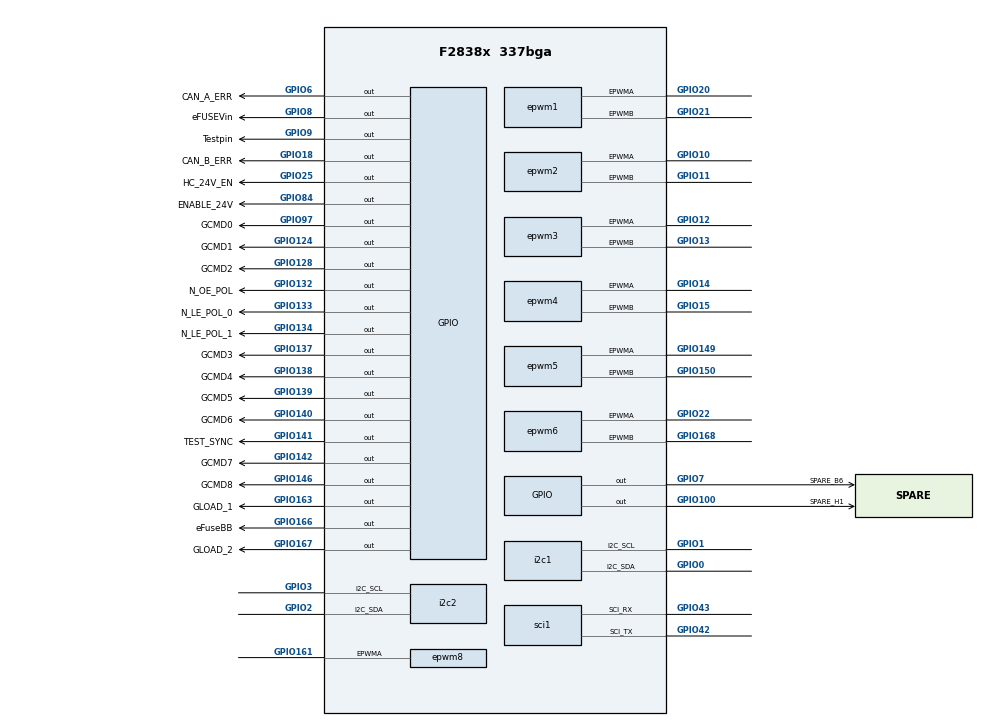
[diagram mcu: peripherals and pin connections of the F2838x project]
/**
 * @cliArgs --device "F2838x" --package "337bga" --part "F2838x_337bga" --context "CPU1" --product "C2000WARE@4.02.00.00"
 * @versions {"tool":"1.17.0+3128"}
 */

/**
 * Import the modules used in this configuration.
 */
const cputimer         = scripting.addModule("/driverlib/cputimer.js", {}, false);
const cputimer1        = cputimer.addInstance();
const dma              = scripting.addModule("/driverlib/dma.js", {}, false);
const dma1             = dma.addInstance();
const epwm             = scripting.addModule("/driverlib/epwm.js", {}, false);
const epwm1            = epwm.addInstance();
const epwm2            = epwm.addInstance();
const epwm3            = epwm.addInstance();
const epwm4            = epwm.addInstance();
const epwm5            = epwm.addInstance();
const epwm6            = epwm.addInstance();
const epwm7            = epwm.addInstance();
const epwm8            = epwm.addInstance();
const gpio             = scripting.addModule("/driverlib/gpio.js", {}, false);
const gpio1            = gpio.addInstance();
const gpio2            = gpio.addInstance();
const gpio3            = gpio.addInstance();
const gpio4            = gpio.addInstance();
const gpio5            = gpio.addInstance();
const gpio6            = gpio.addInstance();
const gpio7            = gpio.addInstance();
const gpio8            = gpio.addInstance();
const gpio9            = gpio.addInstance();
const gpio10           = gpio.addInstance();
const gpio11           = gpio.addInstance();
const gpio12           = gpio.addInstance();
const gpio13           = gpio.addInstance();
const gpio14           = gpio.addInstance();
const gpio15           = gpio.addInstance();
const gpio16           = gpio.addInstance();
const gpio17           = gpio.addInstance();
const gpio18           = gpio.addInstance();
const gpio19           = gpio.addInstance();
const gpio20           = gpio.addInstance();
const gpio21           = gpio.addInstance();
const gpio22           = gpio.addInstance();
const gpio23           = gpio.addInstance();
const gpio24           = gpio.addInstance();
const i2c              = scripting.addModule("/driverlib/i2c.js", {}, false);
const i2c1             = i2c.addInstance();
const i2c2             = i2c.addInstance();
const inputxbar_input  = scripting.addModule("/driverlib/inputxbar_input.js", {}, false);
const inputxbar_input1 = inputxbar_input.addInstance();
const inputxbar_input2 = inputxbar_input.addInstance();
const inputxbar_input3 = inputxbar_input.addInstance();
const memcfg           = scripting.addModule("/driverlib/memcfg.js");
const sci              = scripting.addModule("/driverlib/sci.js", {}, false);
const sci1             = sci.addInstance();
const sysctl           = scripting.addModule("/driverlib/sysctl.js");

/**
 * Write custom configuration values to the imported modules.
 */
cputimer1.cputimerBase             = "CPUTIMER2_BASE";
cputimer1.timerPrescaler           = 1000;
cputimer1.timerPeriod              = 200;
cputimer1.registerInterrupts       = true;
cputimer1.startTimer               = true;
cputimer1.enableInterrupt          = true;
cputimer1.$name                    = "myCPUTIMER2";
cputimer1.timerInt.enableInterrupt = true;

dma1.dmaBase                = "DMA_CH2_BASE";
dma1.useInterrupts          = true;
dma1.interruptMode          = "DMA_INT_AT_END";
dma1.$name                  = "CPU1_EXT_MEM";
dma1.enableTriggers         = true;
dma1.srcBurstStep           = 1;
dma1.destBurstStep          = 1;
dma1.srcAddressVariable     = "srcAddr";
dma1.destAddressVariable    = "destAddr";
dma1.registerInterrupts     = true;
dma1.enableInterrupts       = true;
dma1.destTransferStep       = 1;
dma1.srcTransferStep        = 1;
dma1.burstSize              = 16;
dma1.dmaInt.enableInterrupt = true;

epwm1.$name                                                               = "BEG_1_2";
epwm1.epwmTimebase_period                                                 = 714;
epwm1.epwmActionQualifier_EPWM_AQ_OUTPUT_A_ON_TIMEBASE_ZERO               = "EPWM_AQ_OUTPUT_HIGH";
epwm1.epwmActionQualifier_EPWM_AQ_OUTPUT_A_ON_TIMEBASE_UP_CMPA            = "EPWM_AQ_OUTPUT_LOW";
epwm1.epwmDeadband_polarityFED                                            = "EPWM_DB_POLARITY_ACTIVE_LOW";
epwm1.epwmDeadband_delayRED                                               = 10;
epwm1.epwmDeadband_delayFED                                               = 10;
epwm1.epwmTimebase_hsClockDiv                                             = "EPWM_HSCLOCK_DIVIDER_1";
epwm1.epwmEventTrigger_EPWM_SOC_A_triggerEnable                           = true;
epwm1.epwmEventTrigger_EPWM_SOC_A_triggerSource                           = "EPWM_SOC_TBCTR_ZERO";
epwm1.epwmEventTrigger_EPWM_SOC_B_triggerEnable                           = true;
epwm1.epwmEventTrigger_EPWM_SOC_B_triggerSource                           = "EPWM_SOC_TBCTR_U_CMPA";
epwm1.epwmDeadband_enableRED                                              = true;
epwm1.epwmDeadband_enableFED                                              = true;
epwm1.epwmActionQualifier_EPWM_AQ_OUTPUT_A_shadowMode                     = true;
epwm1.epwmActionQualifier_EPWM_AQ_OUTPUT_A_shadowEvent                    = "EPWM_AQ_LOAD_ON_CNTR_PERIOD";
epwm1.epwmCounterCompare_cmpA                                             = 714;
epwm1.epwmTripZone_oneShotSource                                          = ["EPWM_TZ_SIGNAL_OSHT3"];
epwm1.epwmTripZone_cbcPulse                                               = "EPWM_TZ_CBC_PULSE_CLR_CNTR_PERIOD";
epwm1.epwmTripZone_tzInterruptSource                                      = ["EPWM_TZ_INTERRUPT_OST"];
epwm1.epwmDigitalCompare_EPWM_TZ_DC_OUTPUT_A2                             = "EPWM_TZ_EVENT_DCXH_LOW";
epwm1.epwmDigitalCompare_EPWM_DC_MODULE_A_EPWM_DC_EVENT_1_latchMode       = "EPWM_DC_CBC_LATCH_ENABLED";
epwm1.epwmDigitalCompare_EPWM_DC_MODULE_A_EPWM_DC_EVENT_1_latchClearEvent = "EPWM_DC_CBC_LATCH_CLR_ON_CNTR_PERIOD";
epwm1.epwmDigitalCompare_EPWM_DC_MODULE_A_EPWM_DC_EVENT_2_latchMode       = "EPWM_DC_CBC_LATCH_ENABLED";
epwm1.epwmDigitalCompare_EPWM_DC_MODULE_A_EPWM_DC_EVENT_2_latchClearEvent = "EPWM_DC_CBC_LATCH_CLR_ON_CNTR_PERIOD";
epwm1.epwmDigitalCompare_EPWM_DC_MODULE_B_EPWM_DC_EVENT_1_latchMode       = "EPWM_DC_CBC_LATCH_ENABLED";
epwm1.epwmDigitalCompare_EPWM_DC_MODULE_B_EPWM_DC_EVENT_2_latchMode       = "EPWM_DC_CBC_LATCH_ENABLED";
epwm1.epwmEventTrigger_EPWM_SOC_A_triggerEventPrescalar                   = "2";
epwm1.epwmEventTrigger_EPWM_SOC_A_triggerEventCountInitEnable             = true;
epwm1.epwmEventTrigger_EPWM_SOC_B_triggerEventPrescalar                   = "2";
epwm1.epwmEventTrigger_EPWM_SOC_B_triggerEventCountInitEnable             = true;
epwm1.epwmTimebase_syncInPulseSource                                      = "EPWM_SYNC_IN_PULSE_SRC_DISABLE";
epwm1.epwmTimebase_emulationMode                                          = "EPWM_EMULATION_FREE_RUN";
epwm1.hrpwm_syncSource                                                    = "HRPWM_PWMSYNC_SOURCE_COMPC_UP";
epwm1.epwmTimebase_syncOutPulseMode                                       = ["EPWM_SYNC_OUT_PULSE_ON_CNTR_COMPARE_C"];
epwm1.epwm.$assign                                                        = "EPWM11";
epwm1.epwm.epwmaPin.$assign                                               = "GPIO20";
epwm1.epwm.epwmbPin.$assign                                               = "GPIO21";

epwm2.$name                                                    = "QABPWM_12_13";
epwm2.epwmTimebase_emulationMode                               = "EPWM_EMULATION_FREE_RUN";
epwm2.epwmTimebase_hsClockDiv                                  = "EPWM_HSCLOCK_DIVIDER_1";
epwm2.epwmTimebase_period                                      = 386;
epwm2.epwmTimebase_phaseEnable                                 = true;
epwm2.epwmTimebase_forceSyncPulse                              = true;
epwm2.epwmTimebase_syncInPulseSource                           = "EPWM_SYNC_IN_PULSE_SRC_DISABLE";
epwm2.epwmTimebase_syncOutPulseMode                            = ["EPWM_SYNC_OUT_PULSE_ON_CNTR_COMPARE_C"];
epwm2.hrpwm_syncSource                                         = "HRPWM_PWMSYNC_SOURCE_COMPC_UP";
epwm2.epwmCounterCompare_cmpA                                  = 193;
epwm2.epwmActionQualifier_EPWM_AQ_OUTPUT_A_ON_TIMEBASE_ZERO    = "EPWM_AQ_OUTPUT_HIGH";
epwm2.epwmActionQualifier_EPWM_AQ_OUTPUT_A_ON_TIMEBASE_UP_CMPA = "EPWM_AQ_OUTPUT_LOW";
epwm2.epwmTripZone_EPWM_TZ_ACTION_EVENT_TZA                    = "EPWM_TZ_ACTION_LOW";
epwm2.epwmTripZone_EPWM_TZ_ACTION_EVENT_TZB                    = "EPWM_TZ_ACTION_LOW";
epwm2.epwmTripZone_cbcSource                                   = ["EPWM_TZ_SIGNAL_DCAEVT2"];
epwm2.epwmDeadband_polarityFED                                 = "EPWM_DB_POLARITY_ACTIVE_LOW";
epwm2.epwmDeadband_enableRED                                   = true;
epwm2.epwmDeadband_delayRED                                    = 4;
epwm2.epwmDeadband_enableFED                                   = true;
epwm2.epwmDeadband_delayFED                                    = 4;
epwm2.epwm.$assign                                             = "EPWM6";
epwm2.epwm.epwmaPin.$assign                                    = "GPIO10";
epwm2.epwm.epwmbPin.$assign                                    = "GPIO11";

epwm3.$name                                                    = "QABPWM_14_15";
epwm3.epwmTimebase_emulationMode                               = "EPWM_EMULATION_FREE_RUN";
epwm3.epwmTimebase_hsClockDiv                                  = "EPWM_HSCLOCK_DIVIDER_1";
epwm3.epwmTimebase_period                                      = 386;
epwm3.epwmTimebase_periodLink                                  = "EPWM_LINK_WITH_EPWM_6";
epwm3.epwmTimebase_phaseEnable                                 = true;
epwm3.epwmTimebase_phaseShift                                  = 2;
epwm3.epwmTimebase_syncInPulseSource                           = "EPWM_SYNC_IN_PULSE_SRC_SYNCOUT_EPWM6";
epwm3.hrpwm_syncSource                                         = "HRPWM_PWMSYNC_SOURCE_COMPC_UP";
epwm3.epwmCounterCompare_cmpA                                  = 193;
epwm3.epwmCounterCompare_cmpALink                              = "EPWM_LINK_WITH_EPWM_6";
epwm3.epwmActionQualifier_EPWM_AQ_OUTPUT_A_ON_TIMEBASE_ZERO    = "EPWM_AQ_OUTPUT_HIGH";
epwm3.epwmActionQualifier_EPWM_AQ_OUTPUT_A_ON_TIMEBASE_UP_CMPA = "EPWM_AQ_OUTPUT_LOW";
epwm3.epwmDeadband_polarityFED                                 = "EPWM_DB_POLARITY_ACTIVE_LOW";
epwm3.epwmDeadband_enableRED                                   = true;
epwm3.epwmDeadband_delayRED                                    = 4;
epwm3.epwmDeadband_enableFED                                   = true;
epwm3.epwmDeadband_delayFED                                    = 4;
epwm3.epwmDeadband_outputSwapOutA                              = true;
epwm3.epwmDeadband_outputSwapOutB                              = true;
epwm3.epwm.$assign                                             = "EPWM7";
epwm3.epwm.epwmaPin.$assign                                    = "GPIO12";
epwm3.epwm.epwmbPin.$assign                                    = "GPIO13";

epwm4.$name                                                    = "QABPWM_4_5";
epwm4.epwmTimebase_hsClockDiv                                  = "EPWM_HSCLOCK_DIVIDER_1";
epwm4.epwmTimebase_period                                      = 386;
epwm4.epwmTimebase_syncInPulseSource                           = "EPWM_SYNC_IN_PULSE_SRC_DISABLE";
epwm4.epwmTimebase_syncOutPulseMode                            = ["EPWM_SYNC_OUT_PULSE_ON_CNTR_ZERO"];
epwm4.epwmCounterCompare_cmpA                                  = 193;
epwm4.epwmActionQualifier_EPWM_AQ_OUTPUT_A_ON_TIMEBASE_ZERO    = "EPWM_AQ_OUTPUT_HIGH";
epwm4.epwmActionQualifier_EPWM_AQ_OUTPUT_A_ON_TIMEBASE_UP_CMPA = "EPWM_AQ_OUTPUT_LOW";
epwm4.epwmTripZone_EPWM_TZ_ACTION_EVENT_TZA                    = "EPWM_TZ_ACTION_LOW";
epwm4.epwmTripZone_EPWM_TZ_ACTION_EVENT_TZB                    = "EPWM_TZ_ACTION_LOW";
epwm4.epwmTripZone_cbcSource                                   = ["EPWM_TZ_SIGNAL_DCAEVT2"];
epwm4.epwmDeadband_polarityFED                                 = "EPWM_DB_POLARITY_ACTIVE_LOW";
epwm4.epwmDeadband_enableRED                                   = true;
epwm4.epwmDeadband_delayRED                                    = 4;
epwm4.epwmDeadband_enableFED                                   = true;
epwm4.epwmDeadband_delayFED                                    = 4;
epwm4.epwm.$assign                                             = "EPWM8";
epwm4.epwm.epwmaPin.$assign                                    = "GPIO14";
epwm4.epwm.epwmbPin.$assign                                    = "GPIO15";

epwm5.$name                          = "QABPWM_6_7";
epwm5.epwmTimebase_hsClockDiv        = "EPWM_HSCLOCK_DIVIDER_1";
epwm5.epwmTimebase_period            = 386;
epwm5.epwmTimebase_periodLink        = "EPWM_LINK_WITH_EPWM_8";
epwm5.epwmTimebase_phaseEnable       = true;
epwm5.epwmTimebase_phaseShift        = 2;
epwm5.epwmTimebase_forceSyncPulse    = true;
epwm5.epwmTimebase_syncInPulseSource = "EPWM_SYNC_IN_PULSE_SRC_SYNCOUT_EPWM8";
epwm5.epwmTimebase_syncOutPulseMode  = ["EPWM_SYNC_OUT_PULSE_ON_CNTR_ZERO"];
epwm5.epwmCounterCompare_cmpA        = 193;
epwm5.epwmCounterCompare_cmpALink    = "EPWM_LINK_WITH_EPWM_8";
epwm5.epwmDeadband_polarityFED       = "EPWM_DB_POLARITY_ACTIVE_LOW";
epwm5.epwmDeadband_enableRED         = true;
epwm5.epwmDeadband_delayRED          = 4;
epwm5.epwmDeadband_enableFED         = true;
epwm5.epwmDeadband_delayFED          = 4;
epwm5.epwmDeadband_outputSwapOutB    = true;
epwm5.epwmDeadband_outputSwapOutA    = true;
epwm5.epwm.epwmaPin.$assign          = "GPIO149";
epwm5.epwm.epwmbPin.$assign          = "GPIO150";

epwm6.copyFrom                                                 = "BEG_1_2";
epwm6.epwmTimebase_hsClockDiv                                  = "EPWM_HSCLOCK_DIVIDER_1";
epwm6.epwmActionQualifier_EPWM_AQ_OUTPUT_B_ON_TIMEBASE_ZERO    = "EPWM_AQ_OUTPUT_HIGH";
epwm6.epwmEventTrigger_EPWM_SOC_A_triggerEnable                = true;
epwm6.epwmCounterCompare_cmpB                                  = 500;
epwm6.epwmEventTrigger_EPWM_SOC_A_triggerSource                = "EPWM_SOC_TBCTR_ZERO";
epwm6.$name                                                    = "InrushCurrentLimit";
epwm6.epwmTimebase_period                                      = 10000;
epwm6.epwmCounterCompare_cmpC                                  = 8500;
epwm6.epwmActionQualifier_EPWM_AQ_OUTPUT_B_ON_TIMEBASE_UP_CMPA = "EPWM_AQ_OUTPUT_LOW";
epwm6.epwmDeadband_inputRED                                    = "EPWM_DB_INPUT_EPWMB";
epwm6.epwmDeadband_inputFED                                    = "EPWM_DB_INPUT_EPWMB";
epwm6.epwmEventTrigger_EPWM_SOC_A_triggerEventPrescalar        = "1";
epwm6.epwmEventTrigger_EPWM_SOC_B_triggerEnable                = true;
epwm6.epwmEventTrigger_EPWM_SOC_B_triggerSource                = "EPWM_SOC_TBCTR_U_CMPC";
epwm6.epwmEventTrigger_EPWM_SOC_B_triggerEventPrescalar        = "1";
epwm6.epwmCounterCompare_cmpA                                  = 1;
epwm6.epwmTripZone_EPWM_TZ_ACTION_EVENT_TZA                    = "EPWM_TZ_ACTION_LOW";
epwm6.epwmTripZone_EPWM_TZ_ACTION_EVENT_TZB                    = "EPWM_TZ_ACTION_LOW";
epwm6.epwm.$assign                                             = "EPWM12";
epwm6.epwm.epwmaPin.$assign                                    = "GPIO22";
epwm6.epwm.epwmbPin.$assign                                    = "GPIO168";

epwm7.$name                                             = "EPWMTimer";
epwm7.epwmTimebase_hsClockDiv                           = "EPWM_HSCLOCK_DIVIDER_1";
epwm7.epwmTimebase_period                               = 1000;
epwm7.epwmTimebase_periodLink                           = "EPWM_LINK_WITH_EPWM_11";
epwm7.epwmTimebase_forceSyncPulse                       = true;
epwm7.epwmTimebase_syncInPulseSource                    = "EPWM_SYNC_IN_PULSE_SRC_SYNCOUT_EPWM11";
epwm7.epwmCounterCompare_cmpA                           = 800;
epwm7.epwmCounterCompare_cmpBLink                       = "EPWM_LINK_WITH_EPWM_11";
epwm7.epwmCounterCompare_cmpCLink                       = "EPWM_LINK_WITH_EPWM_11";
epwm7.epwmCounterCompare_cmpDLink                       = "EPWM_LINK_WITH_EPWM_11";
epwm7.epwmEventTrigger_enableInterrupt                  = true;
epwm7.epwmEventTrigger_EPWM_SOC_A_triggerEnable         = true;
epwm7.epwmEventTrigger_EPWM_SOC_A_triggerSource         = "EPWM_SOC_TBCTR_U_CMPA";
epwm7.epwmEventTrigger_EPWM_SOC_A_triggerEventPrescalar = "10";
epwm7.epwm.$assign                                      = "EPWM16";

epwm8.$name                                                    = "GLOAD_4_3";
epwm8.epwmTimebase_emulationMode                               = "EPWM_EMULATION_FREE_RUN";
epwm8.epwmTimebase_hsClockDiv                                  = "EPWM_HSCLOCK_DIVIDER_1";
epwm8.epwmTimebase_period                                      = 10000;
epwm8.epwmTimebase_counterMode                                 = "EPWM_COUNTER_MODE_UP";
epwm8.epwmTimebase_syncInPulseSource                           = "EPWM_SYNC_IN_PULSE_SRC_DISABLE";
epwm8.epwmCounterCompare_cmpA                                  = 10001;
epwm8.epwmCounterCompare_cmpB                                  = 10001;
epwm8.epwmActionQualifier_EPWM_AQ_OUTPUT_A_ON_TIMEBASE_ZERO    = "EPWM_AQ_OUTPUT_HIGH";
epwm8.epwmActionQualifier_EPWM_AQ_OUTPUT_A_ON_TIMEBASE_UP_CMPA = "EPWM_AQ_OUTPUT_LOW";
epwm8.epwmActionQualifier_EPWM_AQ_OUTPUT_B_ON_TIMEBASE_ZERO    = "EPWM_AQ_OUTPUT_HIGH";
epwm8.epwmActionQualifier_EPWM_AQ_OUTPUT_B_ON_TIMEBASE_UP_CMPB = "EPWM_AQ_OUTPUT_LOW";
epwm8.epwm.$assign                                             = "EPWM9";
epwm8.epwm.epwmaPin.$assign                                    = "GPIO161";

gpio1.$name           = "CAN_A_ERR";
gpio1.masterCore      = "GPIO_CORE_CPU2";
gpio1.gpioPin.$assign = "GPIO6";

gpio2.$name           = "SPARE_B6";
gpio2.masterCore      = "GPIO_CORE_CPU2";
gpio2.gpioPin.$assign = "GPIO7";

gpio3.masterCore      = "GPIO_CORE_CPU2";
gpio3.$name           = "eFUSEVin";
gpio3.gpioPin.$assign = "GPIO8";

gpio4.$name           = "CAN_B_ERR";
gpio4.gpioPin.$assign = "GPIO18";

gpio5.$name           = "HC_24V_EN";
gpio5.masterCore      = "GPIO_CORE_CPU2";
gpio5.gpioPin.$assign = "GPIO25";

gpio6.$name           = "ENABLE_24V";
gpio6.masterCore      = "GPIO_CORE_CPU2";
gpio6.gpioPin.$assign = "GPIO84";

gpio7.$name           = "GCMD0";
gpio7.direction       = "GPIO_DIR_MODE_OUT";
gpio7.masterCore      = "GPIO_CORE_CPU2";
gpio7.gpioPin.$assign = "GPIO97";

gpio8.$name           = "GCMD1";
gpio8.direction       = "GPIO_DIR_MODE_OUT";
gpio8.masterCore      = "GPIO_CORE_CPU2";
gpio8.gpioPin.$assign = "GPIO124";

gpio9.$name           = "GCMD2";
gpio9.direction       = "GPIO_DIR_MODE_OUT";
gpio9.masterCore      = "GPIO_CORE_CPU2";
gpio9.gpioPin.$assign = "GPIO128";

gpio10.$name           = "GCMD3";
gpio10.direction       = "GPIO_DIR_MODE_OUT";
gpio10.masterCore      = "GPIO_CORE_CPU2";
gpio10.gpioPin.$assign = "GPIO137";

gpio11.$name           = "GCMD4";
gpio11.direction       = "GPIO_DIR_MODE_OUT";
gpio11.masterCore      = "GPIO_CORE_CPU2";
gpio11.gpioPin.$assign = "GPIO138";

gpio12.$name           = "GCMD5";
gpio12.direction       = "GPIO_DIR_MODE_OUT";
gpio12.masterCore      = "GPIO_CORE_CPU2";
gpio12.gpioPin.$assign = "GPIO139";

gpio13.$name           = "GCMD6";
gpio13.direction       = "GPIO_DIR_MODE_OUT";
gpio13.masterCore      = "GPIO_CORE_CPU2";
gpio13.gpioPin.$assign = "GPIO140";

gpio14.$name             = "GCMD7";
gpio14.direction         = "GPIO_DIR_MODE_OUT";
gpio14.writeInitialValue = true;
gpio14.initialValue      = 1;
gpio14.masterCore        = "GPIO_CORE_CPU2";
gpio14.gpioPin.$assign   = "GPIO142";

gpio15.$name           = "SPARE_H1";
gpio15.masterCore      = "GPIO_CORE_CPU2";
gpio15.gpioPin.$assign = "GPIO100";

gpio16.$name           = "GLOAD_2";
gpio16.direction       = "GPIO_DIR_MODE_OUT";
gpio16.masterCore      = "GPIO_CORE_CPU2";
gpio16.gpioPin.$assign = "GPIO167";

gpio17.$name             = "N_OE_POL";
gpio17.direction         = "GPIO_DIR_MODE_OUT";
gpio17.writeInitialValue = true;
gpio17.initialValue      = 1;
gpio17.masterCore        = "GPIO_CORE_CPU2";
gpio17.gpioPin.$assign   = "GPIO132";

gpio18.$name           = "N_LE_POL_0";
gpio18.direction       = "GPIO_DIR_MODE_OUT";
gpio18.masterCore      = "GPIO_CORE_CPU2";
gpio18.gpioPin.$assign = "GPIO133";

gpio19.$name           = "N_LE_POL_1";
gpio19.direction       = "GPIO_DIR_MODE_OUT";
gpio19.masterCore      = "GPIO_CORE_CPU2";
gpio19.gpioPin.$assign = "GPIO134";

gpio20.$name           = "Testpin";
gpio20.direction       = "GPIO_DIR_MODE_OUT";
gpio20.masterCore      = "GPIO_CORE_CPU2";
gpio20.gpioPin.$assign = "GPIO9";

gpio21.$name           = "TEST_SYNC";
gpio21.gpioPin.$assign = "GPIO141";

gpio22.$name           = "GLOAD_1";
gpio22.direction       = "GPIO_DIR_MODE_OUT";
gpio22.masterCore      = "GPIO_CORE_CPU2";
gpio22.gpioPin.$assign = "GPIO163";

gpio23.$name           = "eFuseBB";
gpio23.padConfig       = "PULLUP";
gpio23.qualMode        = "GPIO_QUAL_ASYNC";
gpio23.masterCore      = "GPIO_CORE_CPU2";
gpio23.useInterrupt    = true;
gpio23.gpioPin.$assign = "GPIO166";
gpio23.xint.enableInt  = true;

gpio24.$name           = "GCMD8";
gpio24.direction       = "GPIO_DIR_MODE_OUT";
gpio24.masterCore      = "GPIO_CORE_CPU2";
gpio24.gpioPin.$assign = "GPIO146";

i2c1.bitCount               = "I2C_BITCOUNT_8";
i2c1.$name                  = "I2C_BUS";
i2c1.useInterrupts          = false;
i2c1.bitRate                = 50000;
i2c1.i2c.$assign            = "I2CA";
i2c1.i2c.i2c_sdaPin.$assign = "GPIO0";
i2c1.i2c.i2c_sclPin.$assign = "GPIO1";

i2c2.$name                  = "I2C_BUS_B";
i2c2.useInterrupts          = false;
i2c2.bitCount               = "I2C_BITCOUNT_8";
i2c2.i2c.$assign            = "I2CB";
i2c2.i2c.i2c_sdaPin.$assign = "GPIO2";
i2c2.i2c.i2c_sclPin.$assign = "GPIO3";

inputxbar_input1.$name         = "Trip1";
inputxbar_input1.inputxbarGpio = "GPIO8";
inputxbar_input1.inputxbarLock = true;

inputxbar_input2.$name          = "Trip2";
inputxbar_input2.inputxbarInput = "XBAR_INPUT2";
inputxbar_input2.inputxbarGpio  = "GPIO2";

inputxbar_input3.$name         = "Trip3";
inputxbar_input3.inputxbarGpio = "GPIO166";
gpio23.xint.inputxbar          = inputxbar_input3;

memcfg.config_MEMCFG_SECT_GS1 = "MEMCFG_GSRAMMASTER_CPU2";
memcfg.config_MEMCFG_SECT_GS3 = "MEMCFG_GSRAMMASTER_CPU2";

sci1.useFifo                  = false;
sci1.registerInterrupts       = true;
sci1.enabledInterrupts        = ["SCI_INT_RXRDY_BRKDT"];
sci1.enabledErrorInterrupts   = ["SCI_INT_FE","SCI_INT_OE","SCI_INT_PE","SCI_INT_RXERR"];
sci1.$name                    = "cli_serial";
sci1.sci.$assign              = "SCIA";
sci1.sci.sci_rxPin.$assign    = "GPIO43";
sci1.sci.sci_txPin.$assign    = "GPIO42";
sci1.sciRXInt.enableInterrupt = true;
sci1.sciTXInt.enableInterrupt = true;

sysctl.cpuSel_ADCA                = "SYSCTL_CPUSEL_CPU2";
sysctl.cpuSel_ADCB                = "SYSCTL_CPUSEL_CPU2";
sysctl.cpuSel_ADCC                = "SYSCTL_CPUSEL_CPU2";
sysctl.cpuSel_ADCD                = "SYSCTL_CPUSEL_CPU2";
sysctl.cpuSel_EPWM1               = "SYSCTL_CPUSEL_CPU2";
sysctl.cpuSel_EPWM2               = "SYSCTL_CPUSEL_CPU2";
sysctl.cpuSel_EPWM3               = "SYSCTL_CPUSEL_CPU2";
sysctl.cpuSel_EPWM4               = "SYSCTL_CPUSEL_CPU2";
sysctl.cpuSel_EPWM5               = "SYSCTL_CPUSEL_CPU2";
sysctl.cpuSel_EPWM6               = "SYSCTL_CPUSEL_CPU2";
sysctl.cpuSel_EPWM7               = "SYSCTL_CPUSEL_CPU2";
sysctl.cpuSel_EPWM8               = "SYSCTL_CPUSEL_CPU2";
sysctl.cpuSel_EPWM11              = "SYSCTL_CPUSEL_CPU2";
sysctl.cpuSel_EPWM12              = "SYSCTL_CPUSEL_CPU2";
sysctl.cpuSel_EPWM16              = "SYSCTL_CPUSEL_CPU2";
sysctl.cpuSel_EPWM9               = "SYSCTL_CPUSEL_CPU2";
sysctl.cpuSel_EPWM15              = "SYSCTL_CPUSEL_CPU2";
sysctl.cpuSel_EPWM14              = "SYSCTL_CPUSEL_CPU2";
sysctl.cpuSel_EPWM13              = "SYSCTL_CPUSEL_CPU2";
sysctl.cpuSel_EPWM10              = "SYSCTL_CPUSEL_CPU2";
sysctl.standbyQualificationPeriod = 2;

/**
 * Pinmux solution for unlocked pins/peripherals. This ensures that minor changes to the automatic solver in a future
 * version of the tool will not impact the pinmux you originally saw.  These lines can be completely deleted in order to
 * re-solve from scratch.
 */
epwm5.epwm.$suggestSolution          = "EPWM3";
epwm7.epwm.epwmaPin.$suggestSolution = "GPIO143";
epwm7.epwm.epwmbPin.$suggestSolution = "GPIO144";
epwm8.epwm.epwmbPin.$suggestSolution = "GPIO162";
